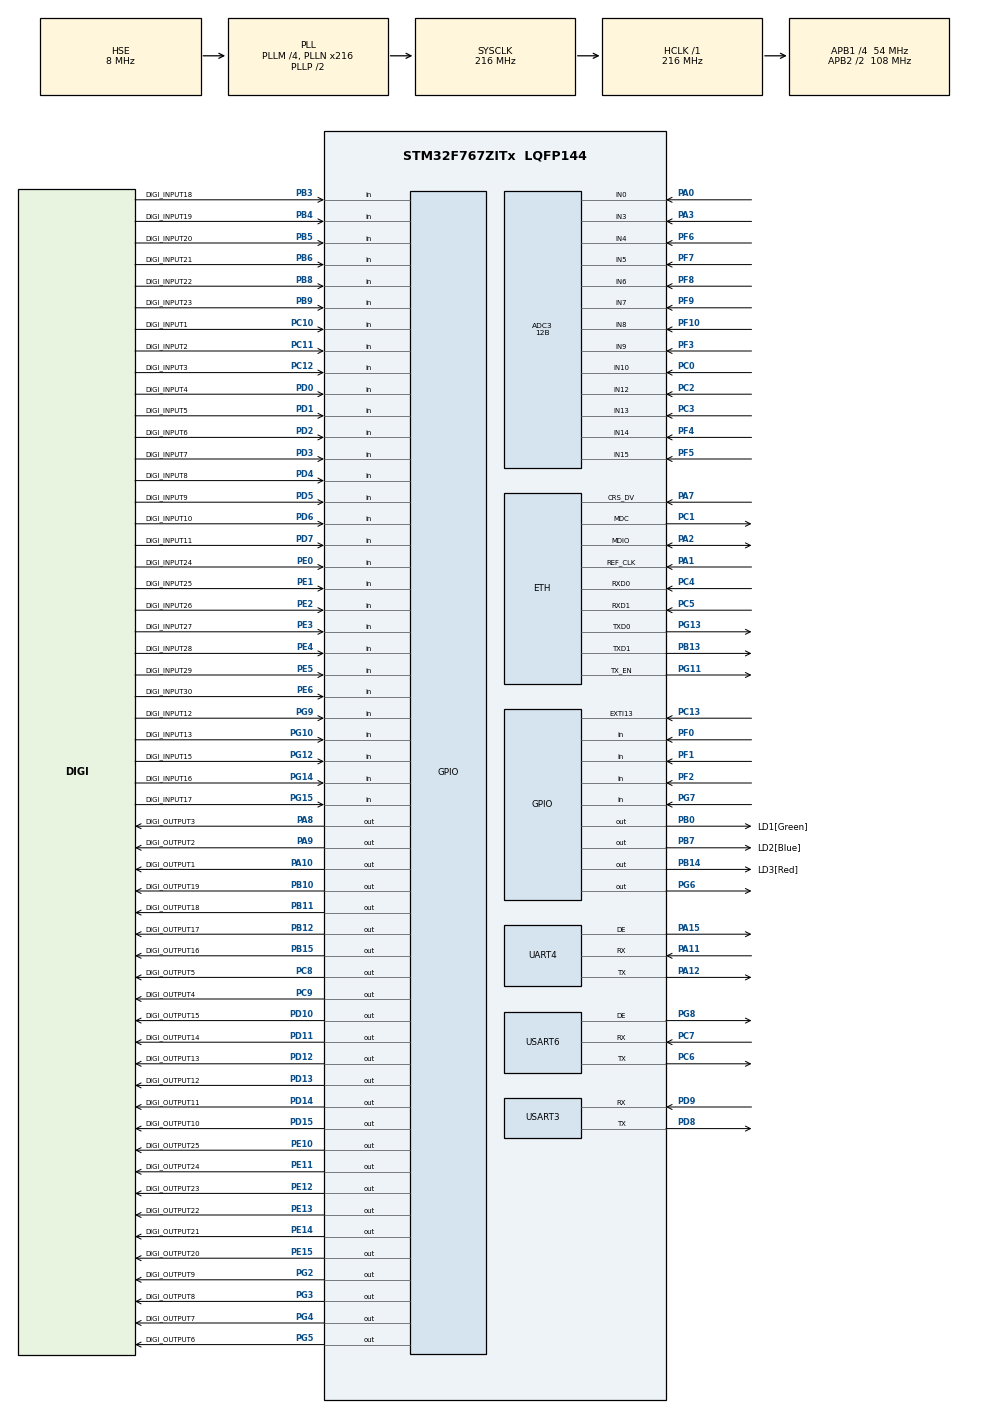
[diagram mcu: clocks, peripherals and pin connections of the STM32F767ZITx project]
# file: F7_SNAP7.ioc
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ADC3.Channel-0\#ChannelRegularConversion=ADC_CHANNEL_0
ADC3.Channel-13\#ChannelRegularConversion=ADC_CHANNEL_3
ADC3.Channel-14\#ChannelRegularConversion=ADC_CHANNEL_4
ADC3.Channel-15\#ChannelRegularConversion=ADC_CHANNEL_5
ADC3.Channel-16\#ChannelRegularConversion=ADC_CHANNEL_6
ADC3.Channel-17\#ChannelRegularConversion=ADC_CHANNEL_7
ADC3.Channel-18\#ChannelRegularConversion=ADC_CHANNEL_8
ADC3.Channel-19\#ChannelRegularConversion=ADC_CHANNEL_9
ADC3.Channel-20\#ChannelRegularConversion=ADC_CHANNEL_10
ADC3.Channel-21\#ChannelRegularConversion=ADC_CHANNEL_12
ADC3.Channel-22\#ChannelRegularConversion=ADC_CHANNEL_13
ADC3.Channel-23\#ChannelRegularConversion=ADC_CHANNEL_14
ADC3.Channel-24\#ChannelRegularConversion=ADC_CHANNEL_15
ADC3.ClockPrescaler=ADC_CLOCK_SYNC_PCLK_DIV4
ADC3.ContinuousConvMode=ENABLE
ADC3.DMAContinuousRequests=ENABLE
ADC3.DataAlign=ADC_DATAALIGN_RIGHT
ADC3.DiscontinuousConvMode=DISABLE
ADC3.EOCSelection=ADC_EOC_SINGLE_CONV
ADC3.EnableAnalogWatchDog=false
ADC3.ExternalTrigConv=ADC_SOFTWARE_START
ADC3.ExternalTrigConvEdge=ADC_EXTERNALTRIGCONVEDGE_NONE
ADC3.InjNumberOfConversion=0
ADC3.NbrOfConversion=13
ADC3.NbrOfConversionFlag=1
ADC3.Rank-0\#ChannelRegularConversion=1
ADC3.Rank-13\#ChannelRegularConversion=2
ADC3.Rank-14\#ChannelRegularConversion=3
ADC3.Rank-15\#ChannelRegularConversion=4
ADC3.Rank-16\#ChannelRegularConversion=5
ADC3.Rank-17\#ChannelRegularConversion=6
ADC3.Rank-18\#ChannelRegularConversion=7
ADC3.Rank-19\#ChannelRegularConversion=8
ADC3.Rank-20\#ChannelRegularConversion=9
ADC3.Rank-21\#ChannelRegularConversion=10
ADC3.Rank-22\#ChannelRegularConversion=11
ADC3.Rank-23\#ChannelRegularConversion=12
ADC3.Rank-24\#ChannelRegularConversion=13
ADC3.Resolution=ADC_RESOLUTION_12B
ADC3.SamplingTime-0\#ChannelRegularConversion=ADC_SAMPLETIME_144CYCLES
ADC3.SamplingTime-13\#ChannelRegularConversion=ADC_SAMPLETIME_144CYCLES
ADC3.SamplingTime-14\#ChannelRegularConversion=ADC_SAMPLETIME_144CYCLES
ADC3.SamplingTime-15\#ChannelRegularConversion=ADC_SAMPLETIME_144CYCLES
ADC3.SamplingTime-16\#ChannelRegularConversion=ADC_SAMPLETIME_144CYCLES
ADC3.SamplingTime-17\#ChannelRegularConversion=ADC_SAMPLETIME_144CYCLES
ADC3.SamplingTime-18\#ChannelRegularConversion=ADC_SAMPLETIME_144CYCLES
ADC3.SamplingTime-19\#ChannelRegularConversion=ADC_SAMPLETIME_144CYCLES
ADC3.SamplingTime-20\#ChannelRegularConversion=ADC_SAMPLETIME_144CYCLES
ADC3.SamplingTime-21\#ChannelRegularConversion=ADC_SAMPLETIME_144CYCLES
ADC3.SamplingTime-22\#ChannelRegularConversion=ADC_SAMPLETIME_144CYCLES
ADC3.SamplingTime-23\#ChannelRegularConversion=ADC_SAMPLETIME_144CYCLES
ADC3.SamplingTime-24\#ChannelRegularConversion=ADC_SAMPLETIME_144CYCLES
ADC3.ScanConvMode=ENABLE
CORTEX_M7.ART_ACCLERATOR_ENABLE=0
CORTEX_M7.CPU_ICache=Disabled
CORTEX_M7.PREFETCH_ENABLE=0
Dma.ADC3.0.Direction=DMA_PERIPH_TO_MEMORY
Dma.ADC3.0.FIFOMode=DMA_FIFOMODE_DISABLE
Dma.ADC3.0.Instance=DMA2_Stream0
Dma.ADC3.0.MemDataAlignment=DMA_MDATAALIGN_HALFWORD
Dma.ADC3.0.MemInc=DMA_MINC_ENABLE
Dma.ADC3.0.Mode=DMA_CIRCULAR
Dma.ADC3.0.PeriphDataAlignment=DMA_PDATAALIGN_HALFWORD
Dma.ADC3.0.PeriphInc=DMA_PINC_DISABLE
Dma.ADC3.0.Priority=DMA_PRIORITY_LOW
Dma.Request0=ADC3
ETH.MediaInterface=ETH_MEDIA_INTERFACE_RMII
ETH.PHY_Name=LAN8742A_PHY_ADDRESS
ETH.PHY_Value=0
ETH.PhyAddress=0
FREERTOS.Queues01=modbusTcpRxQueue,100,uint8_t,0,Dynamic,NULL,NULL;modbusRtuQueue,100,uint8_t,0,Dynamic,NULL,NULL;modbusAsciiQueue,100,uint8_t,0,Dynamic,NULL,NULL
FREERTOS.Tasks01=SysTask,0,128,StartSysTask,Default,NULL,Dynamic,NULL,NULL
FREERTOS.configTOTAL_HEAP_SIZE=131072
FREERTOS.configUSE_MALLOC_FAILED_HOOK=1
LWIP.GATEWAY_ADDRESS=192.168.001.001
LWIP.IP_ADDRESS=192.168.001.123
LWIP.LWIP_DHCP=0
LWIP.LWIP_DNS=0
LWIP.LWIP_NETIF_LINK_CALLBACK=1
LWIP.LWIP_NETIF_STATUS_CALLBACK=1
LWIP.MEMP_NUM_NETBUF=8
LWIP.MEMP_NUM_NETCONN=8
LWIP.MEMP_OVERFLOW_CHECK=0
LWIP.NETMASK_ADDRESS=255.255.255.000
LWIP.Version=v2.0.3_Cube
Mcu.Family=STM32F7
Mcu.Name=STM32F767ZITx
Mcu.Package=LQFP144
NVIC.DMA2_Stream0_IRQn=true\:5\:0\:false\:false\:true\:true\:false
NVIC.ETH_IRQn=true\:5\:0\:false\:false\:true\:true\:false
NVIC.EXTI15_10_IRQn=true\:5\:0\:false\:false\:true\:true\:true
NVIC.PriorityGroup=NVIC_PRIORITYGROUP_4
NVIC.UART4_IRQn=true\:5\:0\:false\:false\:true\:true\:true
NVIC.USART6_IRQn=true\:5\:0\:false\:false\:true\:true\:true
PA0/WKUP.Signal=ADCx_IN0
PA1.GPIO_Mode=GPIO_MODE_AF_PP
PA1.GPIO_PuPd=GPIO_NOPULL
PA1.GPIO_Speed=GPIO_SPEED_FREQ_VERY_HIGH
PA1.Mode=RMII
PA1.Signal=ETH_REF_CLK
PA10.GPIO_Label=DIGI_OUTPUT1
PA10.Signal=GPIO_Output
PA11.Mode=Asynchronous
PA11.Signal=UART4_RX
PA12.Mode=Asynchronous
PA12.Signal=UART4_TX
PA13.Mode=Serial_Wire
PA13.Signal=SYS_JTMS-SWDIO
PA14.Mode=Serial_Wire
PA14.Signal=SYS_JTCK-SWCLK
PA15.Mode=Hardware Flow Control (RS485)
PA15.Signal=UART4_DE
PA2.GPIO_Mode=GPIO_MODE_AF_PP
PA2.GPIO_PuPd=GPIO_NOPULL
PA2.GPIO_Speed=GPIO_SPEED_FREQ_VERY_HIGH
PA2.Mode=RMII
PA2.Signal=ETH_MDIO
PA3.Signal=ADCx_IN3
PA7.GPIO_Mode=GPIO_MODE_AF_PP
PA7.GPIO_PuPd=GPIO_NOPULL
PA7.GPIO_Speed=GPIO_SPEED_FREQ_VERY_HIGH
PA7.Mode=RMII
PA7.Signal=ETH_CRS_DV
PA8.GPIO_Label=DIGI_OUTPUT3
PA8.Signal=GPIO_Output
PA9.GPIO_Label=DIGI_OUTPUT2
PA9.Signal=GPIO_Output
PB0.GPIO_Label=LD1[Green]
PB0.GPIO_ModeDefaultOutputPP=GPIO_MODE_OUTPUT_PP
PB0.GPIO_PuPd=GPIO_NOPULL
PB0.GPIO_Speed=GPIO_SPEED_FREQ_LOW
PB0.PinState=GPIO_PIN_RESET
PB0.Signal=GPIO_Output
PB10.GPIO_Label=DIGI_OUTPUT19
PB10.Signal=GPIO_Output
PB11.GPIO_Label=DIGI_OUTPUT18
PB11.Signal=GPIO_Output
PB12.GPIO_Label=DIGI_OUTPUT17
PB12.Signal=GPIO_Output
PB13.GPIO_Mode=GPIO_MODE_AF_PP
PB13.GPIO_PuPd=GPIO_NOPULL
PB13.GPIO_Speed=GPIO_SPEED_FREQ_VERY_HIGH
PB13.Mode=RMII
PB13.Signal=ETH_TXD1
PB14.GPIO_Label=LD3[Red]
PB14.GPIO_ModeDefaultOutputPP=GPIO_MODE_OUTPUT_PP
PB14.GPIO_PuPd=GPIO_NOPULL
PB14.GPIO_Speed=GPIO_SPEED_FREQ_LOW
PB14.PinState=GPIO_PIN_RESET
PB14.Signal=GPIO_Output
PB15.GPIO_Label=DIGI_OUTPUT16
PB15.Signal=GPIO_Output
PB3.GPIO_Label=DIGI_INPUT18
PB3.Signal=GPIO_Input
PB4.GPIO_Label=DIGI_INPUT19
PB4.Signal=GPIO_Input
PB5.GPIO_Label=DIGI_INPUT20
PB5.Signal=GPIO_Input
PB6.GPIO_Label=DIGI_INPUT21
PB6.Signal=GPIO_Input
PB7.GPIO_FM7=__NULL
PB7.GPIO_Label=LD2[Blue]
PB7.GPIO_ModeDefaultOutputPP=GPIO_MODE_OUTPUT_PP
PB7.GPIO_PuPd=GPIO_NOPULL
PB7.GPIO_Speed=GPIO_SPEED_FREQ_LOW
PB7.PinState=GPIO_PIN_RESET
PB7.Signal=GPIO_Output
PB8.GPIO_Label=DIGI_INPUT22
PB8.Signal=GPIO_Input
PB9.GPIO_Label=DIGI_INPUT23
PB9.Signal=GPIO_Input
PC0.Signal=ADCx_IN10
PC1.GPIO_Mode=GPIO_MODE_AF_PP
PC1.GPIO_PuPd=GPIO_NOPULL
PC1.GPIO_Speed=GPIO_SPEED_FREQ_VERY_HIGH
PC1.Mode=RMII
PC1.Signal=ETH_MDC
PC10.GPIO_Label=DIGI_INPUT1
PC10.Signal=GPIO_Input
PC11.GPIO_Label=DIGI_INPUT2
PC11.Signal=GPIO_Input
PC12.GPIO_Label=DIGI_INPUT3
PC12.Signal=GPIO_Input
PC13.GPIO_ModeDefaultEXTI=GPIO_MODE_IT_RISING
PC13.GPIO_PuPd=GPIO_NOPULL
PC13.Signal=GPXTI13
PC14/OSC32_IN.Mode=LSE-External-Oscillator
PC14/OSC32_IN.Signal=RCC_OSC32_IN
PC15/OSC32_OUT.Mode=LSE-External-Oscillator
PC15/OSC32_OUT.Signal=RCC_OSC32_OUT
PC2.Signal=ADCx_IN12
PC3.Signal=ADCx_IN13
PC4.GPIO_Mode=GPIO_MODE_AF_PP
PC4.GPIO_PuPd=GPIO_NOPULL
PC4.GPIO_Speed=GPIO_SPEED_FREQ_VERY_HIGH
PC4.Mode=RMII
PC4.Signal=ETH_RXD0
PC5.GPIO_Mode=GPIO_MODE_AF_PP
PC5.GPIO_PuPd=GPIO_NOPULL
PC5.GPIO_Speed=GPIO_SPEED_FREQ_VERY_HIGH
PC5.Mode=RMII
PC5.Signal=ETH_RXD1
PC6.Mode=Asynchronous
PC6.Signal=USART6_TX
PC7.Mode=Asynchronous
PC7.Signal=USART6_RX
PC8.GPIO_Label=DIGI_OUTPUT5
PC8.Signal=GPIO_Output
PC9.GPIO_Label=DIGI_OUTPUT4
PC9.Signal=GPIO_Output
PD0.GPIO_Label=DIGI_INPUT4
PD0.Signal=GPIO_Input
PD1.GPIO_Label=DIGI_INPUT5
PD1.Signal=GPIO_Input
PD10.GPIO_Label=DIGI_OUTPUT15
PD10.Signal=GPIO_Output
PD11.GPIO_Label=DIGI_OUTPUT14
PD11.Signal=GPIO_Output
PD12.GPIO_Label=DIGI_OUTPUT13
PD12.Signal=GPIO_Output
PD13.GPIO_Label=DIGI_OUTPUT12
PD13.Signal=GPIO_Output
PD14.GPIO_Label=DIGI_OUTPUT11
PD14.Signal=GPIO_Output
PD15.GPIO_Label=DIGI_OUTPUT10
PD15.Signal=GPIO_Output
PD2.GPIO_Label=DIGI_INPUT6
PD2.Signal=GPIO_Input
PD3.GPIO_Label=DIGI_INPUT7
PD3.Signal=GPIO_Input
PD4.GPIO_Label=DIGI_INPUT8
PD4.Signal=GPIO_Input
PD5.GPIO_Label=DIGI_INPUT9
PD5.Signal=GPIO_Input
PD6.GPIO_Label=DIGI_INPUT10
PD6.Signal=GPIO_Input
PD7.GPIO_Label=DIGI_INPUT11
PD7.Signal=GPIO_Input
PD8.GPIO_ModeDefaultPP=GPIO_MODE_AF_PP
PD8.GPIO_PuPd=GPIO_NOPULL
PD8.GPIO_Speed=GPIO_SPEED_FREQ_VERY_HIGH
PD8.Mode=Asynchronous
PD8.Signal=USART3_TX
PD9.GPIO_ModeDefaultPP=GPIO_MODE_AF_PP
PD9.GPIO_PuPd=GPIO_NOPULL
PD9.GPIO_Speed=GPIO_SPEED_FREQ_VERY_HIGH
PD9.Mode=Asynchronous
PD9.Signal=USART3_RX
PE0.GPIO_Label=DIGI_INPUT24
PE0.Signal=GPIO_Input
PE1.GPIO_Label=DIGI_INPUT25
PE1.Signal=GPIO_Input
PE10.GPIO_Label=DIGI_OUTPUT25
PE10.Signal=GPIO_Output
PE11.GPIO_Label=DIGI_OUTPUT24
PE11.Signal=GPIO_Output
PE12.GPIO_Label=DIGI_OUTPUT23
PE12.Signal=GPIO_Output
PE13.GPIO_Label=DIGI_OUTPUT22
PE13.Signal=GPIO_Output
PE14.GPIO_Label=DIGI_OUTPUT21
PE14.Signal=GPIO_Output
PE15.GPIO_Label=DIGI_OUTPUT20
PE15.Signal=GPIO_Output
PE2.GPIO_Label=DIGI_INPUT26
PE2.Signal=GPIO_Input
PE3.GPIO_Label=DIGI_INPUT27
PE3.Signal=GPIO_Input
PE4.GPIO_Label=DIGI_INPUT28
PE4.Signal=GPIO_Input
PE5.GPIO_Label=DIGI_INPUT29
PE5.Signal=GPIO_Input
PE6.GPIO_Label=DIGI_INPUT30
PE6.Signal=GPIO_Input
PF0.Signal=GPIO_Input
PF1.Signal=GPIO_Input
PF10.GPIO_Mode=GPIO_MODE_ANALOG
PF10.GPIO_PuPd=GPIO_NOPULL
PF10.Mode=IN8
PF10.Signal=ADC3_IN8
PF2.Signal=GPIO_Input
PF3.GPIO_Mode=GPIO_MODE_ANALOG
PF3.GPIO_PuPd=GPIO_NOPULL
PF3.Mode=IN9
PF3.Signal=ADC3_IN9
PF4.GPIO_Mode=GPIO_MODE_ANALOG
PF4.GPIO_PuPd=GPIO_NOPULL
PF4.Mode=IN14
PF4.Signal=ADC3_IN14
PF5.GPIO_Mode=GPIO_MODE_ANALOG
PF5.GPIO_PuPd=GPIO_NOPULL
PF5.Mode=IN15
PF5.Signal=ADC3_IN15
PF6.GPIO_Mode=GPIO_MODE_ANALOG
PF6.GPIO_PuPd=GPIO_NOPULL
PF6.Mode=IN4
PF6.Signal=ADC3_IN4
PF7.GPIO_Mode=GPIO_MODE_ANALOG
PF7.GPIO_PuPd=GPIO_NOPULL
PF7.Mode=IN5
PF7.Signal=ADC3_IN5
PF8.GPIO_Mode=GPIO_MODE_ANALOG
PF8.GPIO_PuPd=GPIO_NOPULL
PF8.Mode=IN6
PF8.Signal=ADC3_IN6
PF9.GPIO_Mode=GPIO_MODE_ANALOG
PF9.GPIO_PuPd=GPIO_NOPULL
PF9.Mode=IN7
PF9.Signal=ADC3_IN7
PG10.GPIO_Label=DIGI_INPUT13
PG10.Signal=GPIO_Input
PG11.GPIO_Mode=GPIO_MODE_AF_PP
PG11.GPIO_PuPd=GPIO_NOPULL
PG11.GPIO_Speed=GPIO_SPEED_FREQ_VERY_HIGH
PG11.Mode=RMII
PG11.Signal=ETH_TX_EN
PG12.GPIO_Label=DIGI_INPUT15
PG12.Signal=GPIO_Input
PG13.GPIO_Mode=GPIO_MODE_AF_PP
PG13.GPIO_PuPd=GPIO_NOPULL
PG13.GPIO_Speed=GPIO_SPEED_FREQ_VERY_HIGH
PG13.Mode=RMII
PG13.Signal=ETH_TXD0
PG14.GPIO_Label=DIGI_INPUT16
PG14.Signal=GPIO_Input
PG15.GPIO_Label=DIGI_INPUT17
PG15.Signal=GPIO_Input
PG2.GPIO_Label=DIGI_OUTPUT9
PG2.Signal=GPIO_Output
PG3.GPIO_Label=DIGI_OUTPUT8
PG3.Signal=GPIO_Output
PG4.GPIO_Label=DIGI_OUTPUT7
PG4.Signal=GPIO_Output
PG5.GPIO_Label=DIGI_OUTPUT6
PG5.Signal=GPIO_Output
PG6.GPIO_ModeDefaultOutputPP=GPIO_MODE_OUTPUT_PP
PG6.GPIO_PuPd=GPIO_NOPULL
PG6.GPIO_Speed=GPIO_SPEED_FREQ_LOW
PG6.PinState=GPIO_PIN_RESET
PG6.Signal=GPIO_Output
PG7.GPIO_Mode=GPIO_MODE_INPUT
PG7.GPIO_PuPd=GPIO_NOPULL
PG7.Signal=GPIO_Input
PG8.Mode=Hardware Flow Control (RS485)
PG8.Signal=USART6_DE
PG9.GPIO_Label=DIGI_INPUT12
PG9.Signal=GPIO_Input
PH0/OSC_IN.Mode=HSE-External-Clock-Source
PH0/OSC_IN.Signal=RCC_OSC_IN
PH1/OSC_OUT.Mode=HSE-External-Clock-Source
PH1/OSC_OUT.Signal=RCC_OSC_OUT
ProjectManager.HeapSize=0x200
ProjectManager.StackSize=0x400
ProjectManager.TargetToolchain=MDK-ARM V5
RCC.48MHZClocksFreq_Value=24000000
RCC.AHBFreq_Value=216000000
RCC.APB1CLKDivider=RCC_HCLK_DIV4
RCC.APB1Freq_Value=54000000
RCC.APB1TimFreq_Value=108000000
RCC.APB2CLKDivider=RCC_HCLK_DIV2
RCC.APB2Freq_Value=108000000
RCC.APB2TimFreq_Value=216000000
RCC.CortexFreq_Value=216000000
RCC.HCLKFreq_Value=216000000
RCC.HSE_VALUE=8000000
RCC.HSI_VALUE=16000000
RCC.PLLM=4
RCC.PLLMUL=RCC_PLL_MUL9
RCC.PLLN=216
RCC.PLLQ=4
RCC.PLLSourceVirtual=RCC_PLLSOURCE_HSE
RCC.PRESCALERUSB=RCC_USBCLKSOURCE_PLL_DIV1_5
RCC.SYSCLKFreq_VALUE=216000000
RCC.SYSCLKSource=RCC_SYSCLKSOURCE_PLLCLK
RCC.SYSCLKSourceVirtual=RCC_SYSCLKSOURCE_PLLCLK
RCC.USBFreq_Value=108000000
RCC.VCOOutputFreq_Value=432000000
SH.ADCx_IN0.0=ADC3_IN0,IN0
SH.ADCx_IN10.0=ADC3_IN10,IN10
SH.ADCx_IN12.0=ADC3_IN12,IN12
SH.ADCx_IN13.0=ADC3_IN13,IN13
SH.ADCx_IN3.0=ADC3_IN3,IN3
UART4.WordLength=WORDLENGTH_8B
USART3.VirtualMode-Asynchronous=VM_ASYNC
USART3.WordLength=WORDLENGTH_8B
USART6.VirtualMode-Asynchronous=VM_ASYNC
USART6.VirtualMode-Hardware\ Flow\ Control\ (RS485)=VM_ASYNC
USART6.WordLength=WORDLENGTH_8B
VP_FREERTOS_VS_ENABLE.Mode=Enabled
VP_LWIP_VS_Enabled.Mode=Enabled
board=NUCLEO-F767ZI

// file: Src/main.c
/**
  ******************************************************************************
  * @file           : main.c
  * @brief          : Main program body
  ******************************************************************************
  * This notice applies to any and all portions of this file
  * that are not between comment pairs USER CODE BEGIN and
  * USER CODE END. Other portions of this file, whether
  * inserted by the user or by software development tools
  * are owned by their respective copyright owners.
  *
  * Copyright (c) 2018 STMicroelectronics International N.V.
  * All rights reserved.
  *
  * Redistribution and use in source and binary forms, with or without
  * modification, are permitted, provided that the following conditions are met:
  *
  * 1. Redistribution of source code must retain the above copyright notice,
  *    this list of conditions and the following disclaimer.
  * 2. Redistributions in binary form must reproduce the above copyright notice,
  *    this list of conditions and the following disclaimer in the documentation
  *    and/or other materials provided with the distribution.
  * 3. Neither the name of STMicroelectronics nor the names of other
  *    contributors to this software may be used to endorse or promote products
  *    derived from this software without specific written permission.
  * 4. This software, including modifications and/or derivative works of this
  *    software, must execute solely and exclusively on microcontroller or
  *    microprocessor devices manufactured by or for STMicroelectronics.
  * 5. Redistribution and use of this software other than as permitted under
  *    this license is void and will automatically terminate your rights under
  *    this license.
  *
  * THIS SOFTWARE IS PROVIDED BY STMICROELECTRONICS AND CONTRIBUTORS "AS IS"
  * AND ANY EXPRESS, IMPLIED OR STATUTORY WARRANTIES, INCLUDING, BUT NOT
  * LIMITED TO, THE IMPLIED WARRANTIES OF MERCHANTABILITY, FITNESS FOR A
  * PARTICULAR PURPOSE AND NON-INFRINGEMENT OF THIRD PARTY INTELLECTUAL PROPERTY
  * RIGHTS ARE DISCLAIMED TO THE FULLEST EXTENT PERMITTED BY LAW. IN NO EVENT
  * SHALL STMICROELECTRONICS OR CONTRIBUTORS BE LIABLE FOR ANY DIRECT, INDIRECT,
  * INCIDENTAL, SPECIAL, EXEMPLARY, OR CONSEQUENTIAL DAMAGES (INCLUDING, BUT NOT
  * LIMITED TO, PROCUREMENT OF SUBSTITUTE GOODS OR SERVICES; LOSS OF USE, DATA,
  * OR PROFITS; OR BUSINESS INTERRUPTION) HOWEVER CAUSED AND ON ANY THEORY OF
  * LIABILITY, WHETHER IN CONTRACT, STRICT LIABILITY, OR TORT (INCLUDING
  * NEGLIGENCE OR OTHERWISE) ARISING IN ANY WAY OUT OF THE USE OF THIS SOFTWARE,
  * EVEN IF ADVISED OF THE POSSIBILITY OF SUCH DAMAGE.
  *
  ******************************************************************************
  */
#include "main.h"
#include "stm32f7xx_hal.h"
#include "cmsis_os.h"
#include "adc.h"
#include "dma.h"
#include "lwip.h"
#include "usart.h"
#include "gpio.h"

/* USER CODE BEGIN PV */
/* Private variables ---------------------------------------------------------*/

/* USER CODE END PV */

void SystemClock_Config(void);
void MX_FREERTOS_Init(void);

/* USER CODE BEGIN PFP */
/* Private function prototypes -----------------------------------------------*/

/* USER CODE END PFP */

int main(void)
{

  /* MCU Configuration----------------------------------------------------------*/

  /* Reset of all peripherals, Initializes the Flash interface and the Systick. */
  HAL_Init();

  /* Configure the system clock */
  SystemClock_Config();

  /* Initialize all configured peripherals */
  MX_GPIO_Init();
  MX_DMA_Init();
  MX_USART3_UART_Init();
  MX_USART6_UART_Init();
  MX_UART4_Init();
  MX_ADC3_Init();

  /* Call init function for freertos objects (in freertos.c) */
  MX_FREERTOS_Init();

  /* Start scheduler */
  osKernelStart();

  /* We should never get here as control is now taken by the scheduler */

  /* Infinite loop */
  while (1)
  {

  }

}

void SystemClock_Config(void)
{

  RCC_OscInitTypeDef RCC_OscInitStruct;
  RCC_ClkInitTypeDef RCC_ClkInitStruct;
  RCC_PeriphCLKInitTypeDef PeriphClkInitStruct;

    /**Configure the main internal regulator output voltage
    */
  __HAL_RCC_PWR_CLK_ENABLE();

  __HAL_PWR_VOLTAGESCALING_CONFIG(PWR_REGULATOR_VOLTAGE_SCALE1);

    /**Initializes the CPU, AHB and APB busses clocks
    */
  RCC_OscInitStruct.OscillatorType = RCC_OSCILLATORTYPE_HSE;
  RCC_OscInitStruct.HSEState = RCC_HSE_BYPASS;
  RCC_OscInitStruct.PLL.PLLState = RCC_PLL_ON;
  RCC_OscInitStruct.PLL.PLLSource = RCC_PLLSOURCE_HSE;
  RCC_OscInitStruct.PLL.PLLM = 4;
  RCC_OscInitStruct.PLL.PLLN = 216;
  RCC_OscInitStruct.PLL.PLLP = RCC_PLLP_DIV2;
  RCC_OscInitStruct.PLL.PLLQ = 4;
  if (HAL_RCC_OscConfig(&RCC_OscInitStruct) != HAL_OK)
  {
    _Error_Handler(__FILE__, __LINE__);
  }

    /**Activate the Over-Drive mode
    */
  if (HAL_PWREx_EnableOverDrive() != HAL_OK)
  {
    _Error_Handler(__FILE__, __LINE__);
  }

    /**Initializes the CPU, AHB and APB busses clocks
    */
  RCC_ClkInitStruct.ClockType = RCC_CLOCKTYPE_HCLK|RCC_CLOCKTYPE_SYSCLK
                              |RCC_CLOCKTYPE_PCLK1|RCC_CLOCKTYPE_PCLK2;
  RCC_ClkInitStruct.SYSCLKSource = RCC_SYSCLKSOURCE_PLLCLK;
  RCC_ClkInitStruct.AHBCLKDivider = RCC_SYSCLK_DIV1;
  RCC_ClkInitStruct.APB1CLKDivider = RCC_HCLK_DIV4;
  RCC_ClkInitStruct.APB2CLKDivider = RCC_HCLK_DIV2;

  if (HAL_RCC_ClockConfig(&RCC_ClkInitStruct, FLASH_LATENCY_7) != HAL_OK)
  {
    _Error_Handler(__FILE__, __LINE__);
  }

  PeriphClkInitStruct.PeriphClockSelection = RCC_PERIPHCLK_USART3|RCC_PERIPHCLK_USART6
                              |RCC_PERIPHCLK_UART4;
  PeriphClkInitStruct.Usart3ClockSelection = RCC_USART3CLKSOURCE_PCLK1;
  PeriphClkInitStruct.Uart4ClockSelection = RCC_UART4CLKSOURCE_PCLK1;
  PeriphClkInitStruct.Usart6ClockSelection = RCC_USART6CLKSOURCE_PCLK2;
  if (HAL_RCCEx_PeriphCLKConfig(&PeriphClkInitStruct) != HAL_OK)
  {
    _Error_Handler(__FILE__, __LINE__);
  }

    /**Configure the Systick interrupt time
    */
  HAL_SYSTICK_Config(HAL_RCC_GetHCLKFreq()/1000);

    /**Configure the Systick
    */
  HAL_SYSTICK_CLKSourceConfig(SYSTICK_CLKSOURCE_HCLK);

  /* SysTick_IRQn interrupt configuration */
  HAL_NVIC_SetPriority(SysTick_IRQn, 15, 0);
}

void _Error_Handler(char *file, int line)
{
  while(1)
  {
  }
}

/************************ (C) COPYRIGHT STMicroelectronics *****END OF FILE****/

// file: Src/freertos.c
/**
  ******************************************************************************
  * File Name          : freertos.c
  * Description        : Code for freertos applications
  ******************************************************************************
  * This notice applies to any and all portions of this file
  * that are not between comment pairs USER CODE BEGIN and
  * USER CODE END. Other portions of this file, whether
  * inserted by the user or by software development tools
  * are owned by their respective copyright owners.
  *
  * Copyright (c) 2018 STMicroelectronics International N.V.
  * All rights reserved.
  *
  * Redistribution and use in source and binary forms, with or without
  * modification, are permitted, provided that the following conditions are met:
  *
  * 1. Redistribution of source code must retain the above copyright notice,
  *    this list of conditions and the following disclaimer.
  * 2. Redistributions in binary form must reproduce the above copyright notice,
  *    this list of conditions and the following disclaimer in the documentation
  *    and/or other materials provided with the distribution.
  * 3. Neither the name of STMicroelectronics nor the names of other
  *    contributors to this software may be used to endorse or promote products
  *    derived from this software without specific written permission.
  * 4. This software, including modifications and/or derivative works of this
  *    software, must execute solely and exclusively on microcontroller or
  *    microprocessor devices manufactured by or for STMicroelectronics.
  * 5. Redistribution and use of this software other than as permitted under
  *    this license is void and will automatically terminate your rights under
  *    this license.
  *
  * THIS SOFTWARE IS PROVIDED BY STMICROELECTRONICS AND CONTRIBUTORS "AS IS"
  * AND ANY EXPRESS, IMPLIED OR STATUTORY WARRANTIES, INCLUDING, BUT NOT
  * LIMITED TO, THE IMPLIED WARRANTIES OF MERCHANTABILITY, FITNESS FOR A
  * PARTICULAR PURPOSE AND NON-INFRINGEMENT OF THIRD PARTY INTELLECTUAL PROPERTY
  * RIGHTS ARE DISCLAIMED TO THE FULLEST EXTENT PERMITTED BY LAW. IN NO EVENT
  * SHALL STMICROELECTRONICS OR CONTRIBUTORS BE LIABLE FOR ANY DIRECT, INDIRECT,
  * INCIDENTAL, SPECIAL, EXEMPLARY, OR CONSEQUENTIAL DAMAGES (INCLUDING, BUT NOT
  * LIMITED TO, PROCUREMENT OF SUBSTITUTE GOODS OR SERVICES; LOSS OF USE, DATA,
  * OR PROFITS; OR BUSINESS INTERRUPTION) HOWEVER CAUSED AND ON ANY THEORY OF
  * LIABILITY, WHETHER IN CONTRACT, STRICT LIABILITY, OR TORT (INCLUDING
  * NEGLIGENCE OR OTHERWISE) ARISING IN ANY WAY OUT OF THE USE OF THIS SOFTWARE,
  * EVEN IF ADVISED OF THE POSSIBILITY OF SUCH DAMAGE.
  *
  ******************************************************************************
  */

#include "FreeRTOS.h"
#include "task.h"
#include "cmsis_os.h"

/* USER CODE BEGIN Includes */
#include "adc.h"
#include "modbus.h"

/* USER CODE END Includes */

osThreadId SysTaskHandle;
osMessageQId modbusTcpRxQueueHandle;
osMessageQId modbusRtuQueueHandle;
osMessageQId modbusAsciiQueueHandle;

/* USER CODE BEGIN Variables */
uint16_t button = 0;
uint8_t button_action = 0;
uint16_t adc_buffer[13];

void StartModbusTask(void const * argument);
osThreadId ModbusTaskHandle;

/* USER CODE END Variables */

void StartSysTask(void const * argument);

extern void MX_LWIP_Init(void);
void MX_FREERTOS_Init(void); /* (MISRA C 2004 rule 8.1) */

/* USER CODE BEGIN FunctionPrototypes */

void HAL_GPIO_EXTI_Callback(uint16_t GPIO_Pin)
{
	if(GPIO_Pin == GPIO_PIN_13)
	{
		button++;
		if(button > 3) button = 0;
		button_action = 1;
	}
}

void HAL_UART_RxCpltCallback(UART_HandleTypeDef *huart)
{
	modbus_acsii_get_input(huart);
//	modbus_rtu_get_input(huart);
}

/* USER CODE END FunctionPrototypes */

/* Hook prototypes */
void vApplicationMallocFailedHook(void);

/* USER CODE BEGIN 5 */
__weak void vApplicationMallocFailedHook(void)
{
   /* vApplicationMallocFailedHook() will only be called if
   configUSE_MALLOC_FAILED_HOOK is set to 1 in FreeRTOSConfig.h. It is a hook
   function that will get called if a call to pvPortMalloc() fails.
   pvPortMalloc() is called internally by the kernel whenever a task, queue,
   timer or semaphore is created. It is also called by various parts of the
   demo application. If heap_1.c or heap_2.c are used, then the size of the
   heap available to pvPortMalloc() is defined by configTOTAL_HEAP_SIZE in
   FreeRTOSConfig.h, and the xPortGetFreeHeapSize() API function can be used
   to query the size of free heap space that remains (although it does not
   provide information on how the remaining heap might be fragmented). */
	printf("vApplicationMallocFailedHook\r\n");
}
/* USER CODE END 5 */

/* Init FreeRTOS */

void MX_FREERTOS_Init(void) {

  /* Create the thread(s) */
  /* definition and creation of SysTask */
  osThreadDef(SysTask, StartSysTask, osPriorityNormal, 0, 128);
  SysTaskHandle = osThreadCreate(osThread(SysTask), NULL);

  /* Create the queue(s) */
  /* definition and creation of modbusTcpRxQueue */
  osMessageQDef(modbusTcpRxQueue, 100, uint8_t);
  modbusTcpRxQueueHandle = osMessageCreate(osMessageQ(modbusTcpRxQueue), NULL);

  /* definition and creation of modbusRtuQueue */
  osMessageQDef(modbusRtuQueue, 100, uint8_t);
  modbusRtuQueueHandle = osMessageCreate(osMessageQ(modbusRtuQueue), NULL);

  /* definition and creation of modbusAsciiQueue */
  osMessageQDef(modbusAsciiQueue, 100, uint8_t);
  modbusAsciiQueueHandle = osMessageCreate(osMessageQ(modbusAsciiQueue), NULL);

}

/* StartSysTask function */
void StartSysTask(void const * argument)
{
  /* init code for LWIP */
//  MX_LWIP_Init();

  /* USER CODE BEGIN StartSysTask */
	modbus_register_init(1,100,50);																																				// register init
//	modbus_ascii_port_init(&huart4,115200,UART_WORDLENGTH_8B,UART_STOPBITS_1,UART_PARITY_NONE);						// modbus ascii init
//	modbus_rtu_port_init(&huart6,115200,UART_WORDLENGTH_8B,UART_STOPBITS_1,UART_PARITY_NONE);							// modbus rtu init
	modbus_tcp_port_init(TCP_SERVER);																																			// modbus tcp init
	printf("modbus init complete\r\n");
	/* Start thread modbus */
	osThreadDef(ModbusTask, StartModbusTask, osPriorityIdle, 0, 128);
  ModbusTaskHandle = osThreadCreate(osThread(ModbusTask), NULL);
	printf("start task handle modbus\r\n");
	HAL_ADC_Start_DMA(&hadc3, (uint32_t*) adc_buffer, 13);
  /* Infinite loop */
  for(;;)
  {
		/* update register analog input */
		for(uint8_t count = 0; count < 13; count++)
		{
			modbus_register_40000[count] = adc_buffer[count];
		}

//		if(button_action != 0)
//		{
//			modbus_tcp_writemultiple_register(1,0,13,adc_buffer);
//			button_action = 0;
//			osDelay(300);
//			modbus_tcp_check_input();
//		}

//		modbus_tcp_readholding_register(1,0,13);
//		osDelay(300);
//		modbus_tcp_check_input();
//		osDelay(1);
		modbus_tcp_check_input();
    osDelay(20);
  }
  /* USER CODE END StartSysTask */
}

/* USER CODE BEGIN Application */

/* StartModbusTask function */
void StartModbusTask(void const * argument)
{
  /* USER CODE BEGIN StartModbusTask */
  /* Infinite loop */
  for(;;)
  {
		HAL_GPIO_TogglePin(GPIOB,GPIO_PIN_0);
    osDelay(500);
  }
  /* USER CODE END StartModbusTask */
}

/* USER CODE END Application */

/************************ (C) COPYRIGHT STMicroelectronics *****END OF FILE****/
